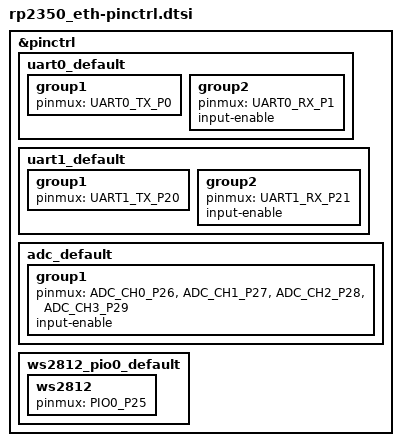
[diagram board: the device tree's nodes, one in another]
/*
 * Copyright (c) 2025 Stephano Cetola
 *
 * SPDX-License-Identifier: Apache-2.0
 */
&pinctrl {
	uart0_default: uart0_default {
		group1 {
			pinmux = <UART0_TX_P0>;
		};

		group2 {
			pinmux = <UART0_RX_P1>;
			input-enable;
		};
	};

	uart1_default: uart1_default {
		group1 {
			pinmux = <UART1_TX_P20>;
		};

		group2 {
			pinmux = <UART1_RX_P21>;
			input-enable;
		};
	};

	adc_default: adc_default {
		group1 {
			pinmux = <ADC_CH0_P26>, <ADC_CH1_P27>, <ADC_CH2_P28>, <ADC_CH3_P29>;
			input-enable;
		};
	};

	ws2812_pio0_default: ws2812_pio0_default {
		ws2812 {
			pinmux = <PIO0_P25>;
		};
	};
};
